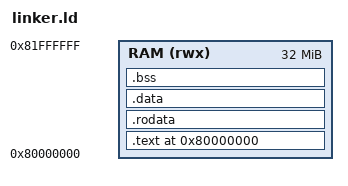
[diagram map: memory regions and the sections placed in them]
ENTRY(_start)

MEMORY
{
  RAM (rwx) : ORIGIN = 0x80000000, LENGTH = 32M
}

SECTIONS
{
  . = ORIGIN(RAM);

  .text : {
    *(.text*)
  } > RAM

  .rodata : {
    *(.rodata*)
  } > RAM

  .data : {
    *(.data*)
  } > RAM

  .bss : {
    *(.bss*)
    *(COMMON)
  } > RAM

  . = ALIGN(8);
  _stack_top = ORIGIN(RAM) + LENGTH(RAM);
}
